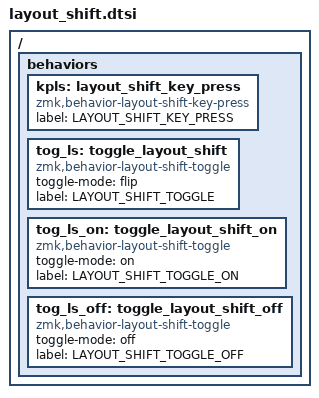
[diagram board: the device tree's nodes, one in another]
/*
 * Copyright (c) 2024 The ZMK Contributors
 *
 * SPDX-License-Identifier: MIT
 */

/* ZMK Layout Shift Module */

#include <dt-bindings/zmk/keys.h>

/ {
    behaviors {
        // Layout-aware key press behavior alias
        kpls: layout_shift_key_press {
            compatible = "zmk,behavior-layout-shift-key-press";
            #binding-cells = <1>;
            label = "LAYOUT_SHIFT_KEY_PRESS";
        };

        // Layout shift toggle behaviors
        tog_ls: toggle_layout_shift {
            compatible = "zmk,behavior-layout-shift-toggle";
            #binding-cells = <0>;
            toggle-mode = "flip";
            label = "LAYOUT_SHIFT_TOGGLE";
        };

        tog_ls_on: toggle_layout_shift_on {
            compatible = "zmk,behavior-layout-shift-toggle";
            #binding-cells = <0>;
            toggle-mode = "on";
            label = "LAYOUT_SHIFT_TOGGLE_ON";
        };

        tog_ls_off: toggle_layout_shift_off {
            compatible = "zmk,behavior-layout-shift-toggle";
            #binding-cells = <0>;
            toggle-mode = "off";
            label = "LAYOUT_SHIFT_TOGGLE_OFF";
        };
    };
};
